# R7FA8M1AH register map
Vendor: Renesas; Series: RA8; File version: 1.2
CPU: CM85 r0p0, little endian, MPU, FPU, VTOR, 4 interrupt priority bits
Registers are 32-bit, read-write, reset 0x0 unless marked. A register's access mark holds for its fields unless they carry their own. Offsets are from the block's base; [hi:lo] are bit positions; {n}, {i} and the like mark numbered series.

## TSN — Temperature Sensor
Base 0x40235000
Same registers: TSN_NS 0x50235000
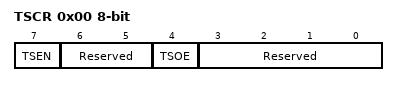
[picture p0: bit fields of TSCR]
0x00 TSCR 8-bit — Temperature Sensor Control Register
  [7] TSEN — Temperature Sensor Output Enable
    0=Stops the temperature sensor; 1=Starts the temperature sensor
  [6:5] Reserved — These bits are read as 00. The write value should be 00.
  [4] TSOE — Temperature Sensor Enable
    0=Disables output from the temperature sensor to the 12-bit A/D converter; 1=Enables output from the temperature sensor to the 12-bit A/D converter
  [3:0] Reserved — These bits are read as 0000. The write value should be 0000.
0x01 TSTRM0 8-bit
0x02 TSTRM1 8-bit
0x03 TSTST 8-bit

## ACMPHS0 — High-Speed Analog Comparator 0
Base 0x40236000
Same registers: ACMPHS1 0x40236100, ACMPHS0_NS 0x50236000, ACMPHS1_NS 0x50236100
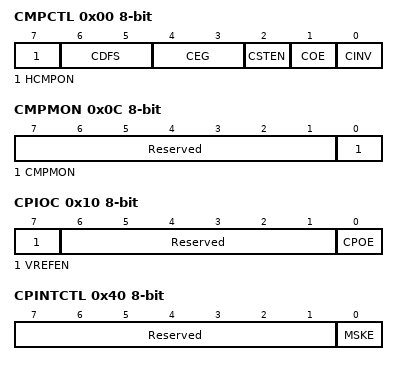
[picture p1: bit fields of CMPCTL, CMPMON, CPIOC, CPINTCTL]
0x00 CMPCTL 8-bit — Comparator Control Register
  [7] HCMPON — Comparator operation control
    0=Operation stopped (the comparator outputs a low-level signal); 1=Operation enabled (input to the comparator pins is enabled
  [6:5] CDFS — Noise filter selection
    0=Noise filter not used; 1=Noise filter sampling frequency is 2^3/PCLKB; 2=Noise filter sampling frequency is 2^4/PCLKB; 3=Noise filter sampling frequency is 2^5/PCLKB
  [4:3] CEG — Selection of valid edge (Edge selector)
    0=No edge selection; 1=Rising edge selection; 2=Falling edge selection; 3=Both-edge selection
  [2] CSTEN — Interrupt Select
    0=Output via the Edge selector; 1=Direct output
  [1] COE — Comparator output enable
    0=Comparator output disabled (the output signal is low level); 1=Comparator output enabled
  [0] CINV — Comparator output polarity selection
    0=Comparator output not inverted; 1=Comparator output inverted
0x04 CMPSEL0 8-bit — Comparator Input Select Register
  [3:0] CMPSEL — Comparator input selection
    0=No input; 1=IVCMP0 selected; 2=IVCMP1 selected; 4=IVCMP2 selected; 8=IVCMP3 selected; other=others (Setting prohibited)
0x08 CMPSEL1 8-bit — Comparator Reference Voltage Select Register
  [3:0] CRVS — Reference voltage selection
    0=No reference voltage; 1=IVREF0 selected; 2=IVREF1 selected; 4=IVREF2 selected; 8=IVREF3 selected; other=others (Setting prohibited)
0x0C CMPMON 8-bit ro — Comparator Output Monitor Register
  [7:1] Reserved — These bits are read as 0000000.
  [0] CMPMON — Comparator output monitor
    0=Comparator output Low; 1=Comparator output High
0x10 CPIOC 8-bit — Comparator Output Control Register
  [7] VREFEN — Internal Vref enable
    0=Internal Vref disable; 1=Internal Vref enable
  [6:1] Reserved — These bits are read as 000000. The write value should be 000000.
  [0] CPOE — Comparator output selection
    0=VCOUT pin output of the comparator is disabled (the output signal is low level); 1=VCOUT pin output of the comparator is enabled
0x40 CPINTCTL 8-bit — Comparator Interrupt Control Register
  [7:1] Reserved — These bits are read as 0000000. The write value should be 0000000.
  [0] MSKE — Comparator Interrupt Periodic Mask Enable
    0=Disable interrupt masking(Default); 1=Enable interrupt masking by GPT output signal selected by CPMSKCTL.MSKSEL[2:0]
0x44 CPMSKCTL 8-bit — Comparator Interrupt Mask Control Register
  [2:0] MSKSEL — Comparator Interrupt Periodic Mask Selection
    {v}=Enable interrupt masking by GTIOC{v}A output signal (v=0..7)

## IIC0WU — Inter-Integrated Circuit 0 Wake-up Unit
Base 0x4025E014
Same registers: IIC0WU_NS 0x5025E014
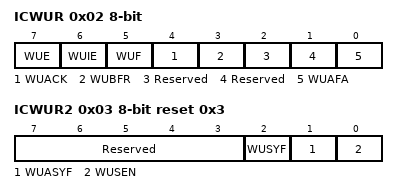
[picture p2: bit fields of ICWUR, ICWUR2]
0x02 ICWUR 8-bit — I2C Bus Wake Up Unit Register
  [7] WUE — Wake Up function Enable
    0=Wake-up function is disabled; 1=Wake-up function is enabled
  [6] WUIE — Wake Up Interrupt Request Enable
    0=Wake Up Interrupt Request (WUI) is disabled; 1=Wake Up Interrupt Request (WUI) is enabled
  [5] WUF — Wake-Up Event Occurrence Flag
    0=Slave address match during Wake-Up function; 1=Slave address not match during Wake-Up function
  [4] WUACK — Asynchronous/Synchronous Operation State Flag
    0=State of synchronous operation; 1=State of asynchronous operation
  [3] WUBFR ro — Bus Free During Wake-Up Mode
    0=IIC bus is busy during Wake-Up mode; 1=IIC bus is free during Wake-Up mode
  [2] Reserved — This bit is read as 0. The write value should be 0.
  [1] Reserved — This bit is read as 0. The write value should be 0.
  [0] WUAFA — Wake-Up Analog Filter Additional Selection
    0=Do not add the Wake Up analog filter; 1=Add the Wake Up analog filter
0x03 ICWUR2 8-bit reset 0x3 — I2C Bus Wake Up Unit Register 2
  [7:3] Reserved — These bits are read as 00000. The write value should be 00000.
  [2] WUSYF ro — Wake-Up function synchronous operation status flag
    0=IIC asynchronous circuit enable condition; 1=IIC synchronous circuit enable condition
  [1] WUASYF ro — Wake-Up function asynchronous operation status flag
    0=IIC synchronous circuit enable condition; 1=IIC asynchronous circuit enable condition
  [0] WUSEN — Wake-Up function synchronous enable
    0=IIC asynchronous circuit enable; 1=IIC synchronous circuit enable
